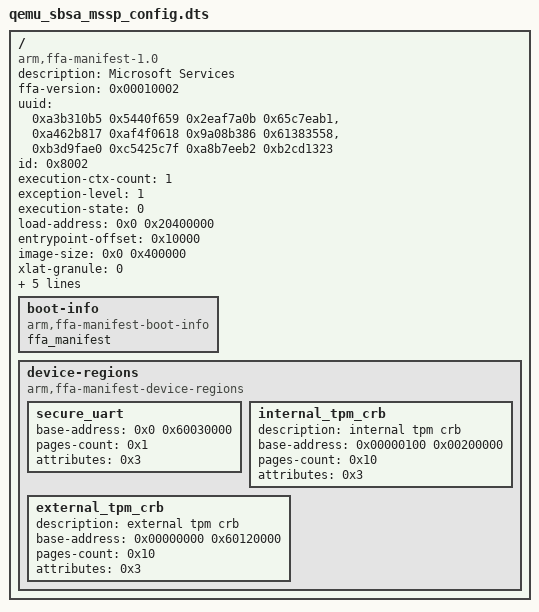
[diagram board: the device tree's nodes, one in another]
/*
 * Copyright (c) 2020-21, ARM Limited and Contributors. All rights reserved.
 *
 * SPDX-License-Identifier: BSD-3-Clause
 */

/dts-v1/;

/ {
#define MODE_SEL0	(1)
#define MODE_SEL1	(2)

#define SECURE_RO 0x1
#define SECURE_RW 0x3
#define SECURE_EXECUTE_RO 0x5
#define SECURE_EXECUTE_RW 0x7
#define NON_SECURE_RO 0x9
#define NON_SECURE_RW 0xB
#define NON_SECURE_EXECUTE_RO 0xD
#define NONSECURE_EXECUTE_RW 0xF
	/*
	 * FF-A compatible Secure Partition Manager parses the
	 * config file and fetch the following booting arguments to
	 * pass on to the StandAloneMM(StMM) Secure Partition.
	 */
	compatible = "arm,ffa-manifest-1.0";

	description = "Microsoft Services";
	ffa-version = <0x00010002>; /* 31:16 - Major, 15:0 - Minor */
	uuid = <0xa3b310b5 0x5440f659 0x2eaf7a0b 0x65c7eab1>, <0xa462b817 0xaf4f0618 0x9a08b386 0x61383558>, <0xb3d9fae0 0xc5425c7f 0xa8b7eeb2 0xb2cd1323>;
	id = <0x8002>;
	execution-ctx-count = <1>;
	exception-level = <1>; /* SEL0*/
	execution-state = <0>; /* AArch64*/
	load-address = <0x0 0x20400000>;
	entrypoint-offset = <0x10000>;
	image-size = <0x0 0x400000>;
	xlat-granule = <0>; /* 4KiB */
	boot-order = <1>;
	messaging-method = <0x603>; /* Direct request/response supported. */
	ns-interrupts-action = <0>; /* Non-secure interrupt is queued */
	notification-support; /* Support receipt of notifications. */
	gp-register-num = <0>;

	boot-info {
		compatible = "arm,ffa-manifest-boot-info";
		ffa_manifest;
	};

	device-regions {
		compatible = "arm,ffa-manifest-device-regions";

		/*
		 * Secure UART region.
		 */
		secure_uart {
			base-address = <0x0 0x60030000>;
			pages-count = <0x1>;
			attributes = <0x3>;
		};

		internal_tpm_crb {
			description = "internal tpm crb";
			base-address = <0x00000100 0x00200000>;
			pages-count = <0x10>;
			attributes = <0x3>;
		};

		external_tpm_crb {
			description = "external tpm crb";
			base-address = <0x00000000 0x60120000>;
			pages-count = <0x10>;
			attributes = <0x3>;
		};
	};
};
